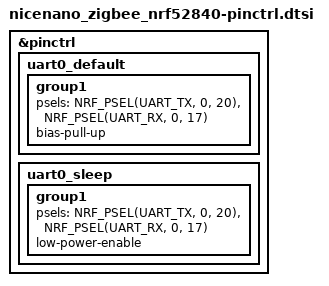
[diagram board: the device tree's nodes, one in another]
#include <zephyr/dt-bindings/pinctrl/nrf-pinctrl.h>

&pinctrl {
    uart0_default: uart0_default {
        group1 {
            psels = <NRF_PSEL(UART_TX, 0, 20)>,
                    <NRF_PSEL(UART_RX, 0, 17)>;
            bias-pull-up;
        };
    };
    uart0_sleep: uart0_sleep {
        group1 {
            psels = <NRF_PSEL(UART_TX, 0, 20)>,
                    <NRF_PSEL(UART_RX, 0, 17)>;
            low-power-enable;
        };
    };
};
